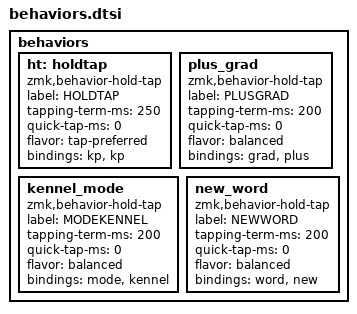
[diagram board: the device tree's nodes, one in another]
    behaviors {
        ht: holdtap {
            compatible = "zmk,behavior-hold-tap";
            label = "HOLDTAP";
            #binding-cells = <2>;
            tapping-term-ms = <250>; //überprüfen
            quick-tap-ms = <0>; //überprüfen
            flavor = "tap-preferred"; //überprüfen
            bindings = <&kp>, <&kp>;
        };

        plus_grad: plus_grad { 
            compatible = "zmk,behavior-hold-tap";
            label = "PLUSGRAD";
            #binding-cells = <2>;
            tapping-term-ms = <200>;
            quick-tap-ms = <0>;
            flavor = "balanced";
            bindings = <&grad>, <&plus>;
        };

        kennel_mode: kennel_mode { 
            compatible = "zmk,behavior-hold-tap";
            label = "MODEKENNEL";
            #binding-cells = <2>;
            tapping-term-ms = <200>;
            quick-tap-ms = <0>;
            flavor = "balanced";
            bindings = <&mode>, <&kennel>;
        };

        new_word: new_word { 
            compatible = "zmk,behavior-hold-tap";
            label = "NEWWORD";
            #binding-cells = <2>;
            tapping-term-ms = <200>;
            quick-tap-ms = <0>;
            flavor = "balanced";
            bindings = <&word>, <&new>;
        };
    };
